# SWM260 register map
File version: 1.0
SWM260 Microcontroller registers
CPU: CM0 r1p0, little endian, 2 interrupt priority bits
Registers are 32-bit, read-write, no defined reset value unless marked. A register's access mark holds for its fields unless they carry their own. Offsets are from the block's base; lines under a group give offsets from that group; [hi:lo] are bit positions; {n}, {i} and the like mark numbered series; 'fields as' and 'values as' point back to an identical list; <NAME> marks a mode.

## Memory map
0x40000000 SYS size 0xAA088 — Registers group
0x40000800 DMA size 0x140 — Registers group
0x40040000 GPIOA size 0x80 — Registers group
0x40040800 GPIOB size 0x80
0x40041000 GPIOC size 0x80
0x40041800 GPIOD size 0x80
0x40042000 UART0 size 0x1C — Registers group
0x40042800 UART1 size 0x1C
0x40043000 UART2 size 0x1C
0x40043800 UART3 size 0x1C
0x40044000 SPI0 size 0x14 — Registers group
0x40044800 SPI1 size 0x14
0x40045000 I2C4 size 0x34 — Registers group
0x40046000 PWM0 size 0x3C — Registers group
0x40046040 PWM1 size 0x3C
0x40046080 PWM2 size 0x3C
0x400460C0 PWM3 size 0x3C
0x40046200 PWMG size 0x48 — Registers group
0x40046800 TIMR0 size 0x30 — Registers group
0x40046840 TIMR1 size 0x30
0x40046880 TIMR2 size 0x30
0x400468C0 TIMR3 size 0x30
0x40046C00 TIMRG size 0x44 — Registers group
0x40048800 BTIMR0 size 0x30
0x40048840 BTIMR1 size 0x30
0x40048880 BTIMR2 size 0x30
0x400488C0 BTIMR3 size 0x30
0x40048C00 BTIMRG size 0x44
0x40049000 ADC0 size 0xFC — Registers group
0x4004A000 FMC size 0x24 — Registers group
0x4004B800 RTC size 0x6C — Registers group
0x400A0000 PORTA size 0x404 — Registers group
0x400A0010 PORTB size 0x404
0x400A0020 PORTC size 0x404
0x400A0030 PORTD size 0x404
0x400A0800 WDT size 0x14 — Registers group
0x400A3000 UART4 size 0x1C

## SYS — Registers group
Base 0x40000000
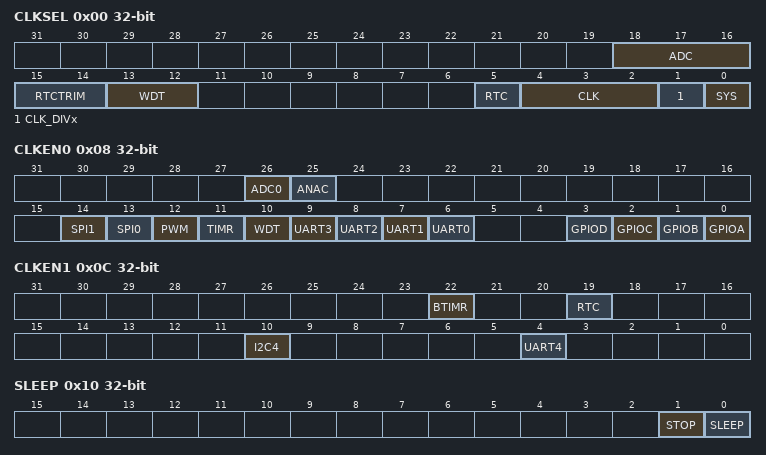
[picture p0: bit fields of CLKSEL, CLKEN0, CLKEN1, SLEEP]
0x00 CLKSEL
  [18:16] ADC, [15:14] RTCTRIM, [13:12] WDT, [5] RTC, [4:2] CLK, [1] CLK_DIVx, [0] SYS
0x04 CLKDIVx_ON
0x08 CLKEN0
  [26] ADC0, [25] ANAC, [14] SPI1, [13] SPI0, [12] PWM, [11] TIMR, [10] WDT, [n+6] UART{n} (n=0..3), [3] GPIOD, [2] GPIOC, [1] GPIOB, [0] GPIOA
0x0C CLKEN1
  [22] BTIMR, [19] RTC, [10] I2C4, [4] UART4
0x10 SLEEP
  [1] STOP, [0] SLEEP
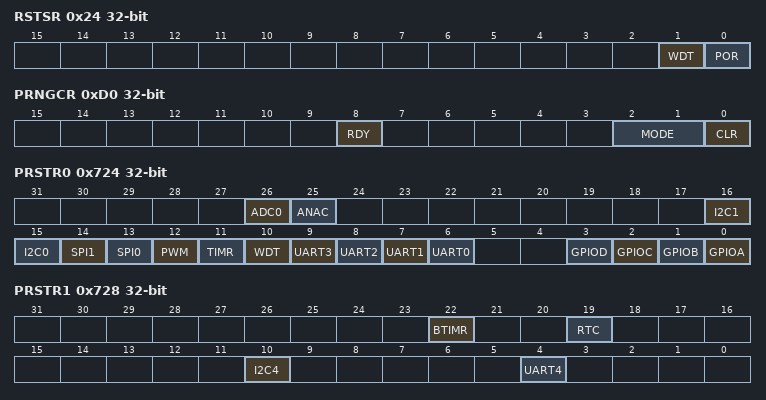
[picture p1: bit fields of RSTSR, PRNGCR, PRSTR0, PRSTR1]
0x24 RSTSR
  [1] WDT, [0] POR
0x30 RTCWKCR
  [0] EN
0x34 RTCWKSR
  [0] FLAG
{0x80+4i} CHIPID[{i}] (i=0..3) ro
{0x90+4i} BACKUP[{i}] (i=0..3)
0xD0 PRNGCR
  [8] RDY, [2:1] MODE, [0] CLR
0xD4 PRNGDL
0xD8 PRNGDH
0x100 PAWKEN
0x104 PBWKEN
0x108 PCWKEN
0x10C PDWKEN
0x130 PAWKSR
0x134 PBWKSR
0x138 PCWKSR
0x13C PDWKSR
0x720 PRSTEN
0x724 PRSTR0
  [26] ADC0, [25] ANAC, [16] I2C1, [15] I2C0, [14] SPI1, [13] SPI0, [12] PWM, [11] TIMR, [10] WDT, [n+6] UART{n} (n=0..3), [3] GPIOD, [2] GPIOC, [1] GPIOB, [0] GPIOA
0x728 PRSTR1
  [22] BTIMR, [19] RTC, [10] I2C4, [4] UART4
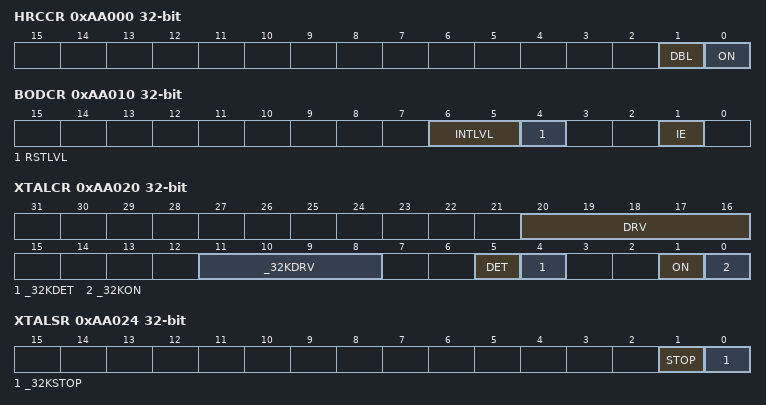
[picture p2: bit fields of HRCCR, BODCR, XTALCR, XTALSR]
0xAA000 HRCCR
  [1] DBL, [0] ON
0xAA010 BODCR
  [6:5] INTLVL, [4] RSTLVL, [1] IE
0xAA014 BODSR
  [0] IF
0xAA020 XTALCR
  [20:16] DRV, [11:8] _32KDRV, [5] DET, [4] _32KDET, [1] ON, [0] _32KON
0xAA024 XTALSR
  [1] STOP, [0] _32KSTOP
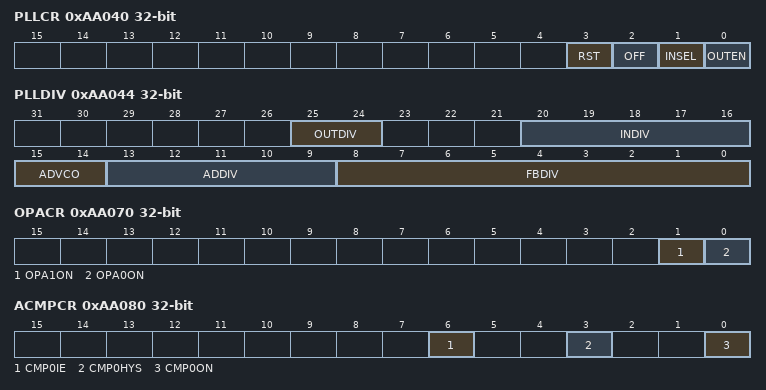
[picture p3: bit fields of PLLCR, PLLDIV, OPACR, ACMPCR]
0xAA040 PLLCR
  [3] RST, [2] OFF, [1] INSEL, [0] OUTEN
0xAA044 PLLDIV
  [25:24] OUTDIV, [20:16] INDIV, [15:14] ADVCO, [13:9] ADDIV, [8:0] FBDIV
0xAA04C PLLLOCK
0xAA050 LRCCR
  [0] ON
0xAA070 OPACR
  [1] OPA1ON, [0] OPA0ON
0xAA080 ACMPCR
  [6] CMP0IE, [3] CMP0HYS, [0] CMP0ON
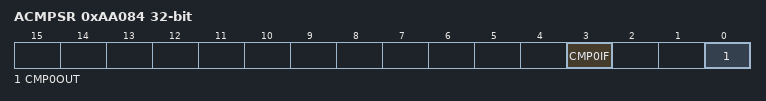
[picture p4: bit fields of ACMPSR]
0xAA084 ACMPSR
  [3] CMP0IF, [0] CMP0OUT

## PORTA — Registers group
Base 0x400A0000
Same registers: PORTB 0x400A0010, PORTC 0x400A0020, PORTD 0x400A0030
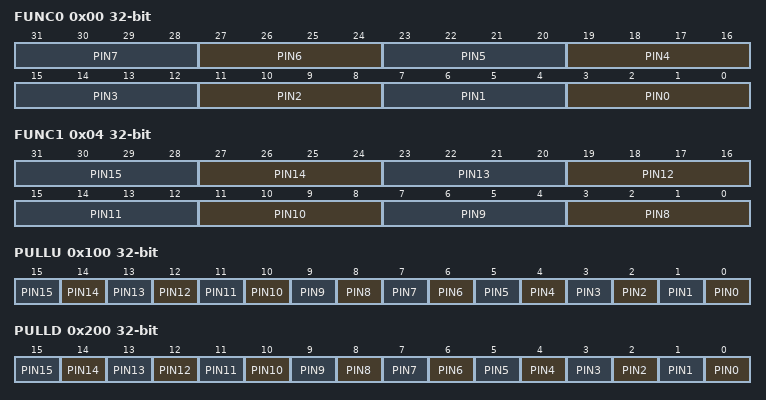
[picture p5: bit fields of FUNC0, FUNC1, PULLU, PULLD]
0x00 FUNC0
  [4n+3:4n] PIN{n} (n=0..7)
0x04 FUNC1
  [4n-29:4n-32] PIN{n} (n=8..15)
0x100 PULLU
  [n] PIN{n} (n=0..15)
0x200 PULLD
  [n] PIN{n} (n=0..15)
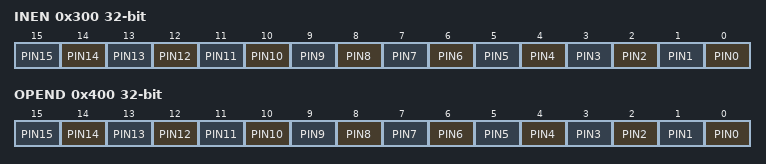
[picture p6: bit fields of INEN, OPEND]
0x300 INEN
  [n] PIN{n} (n=0..15)
0x400 OPEND
  [n] PIN{n} (n=0..15)

## GPIOA — Registers group
Base 0x40040000
Same registers: GPIOB 0x40040800, GPIOC 0x40041000, GPIOD 0x40041800
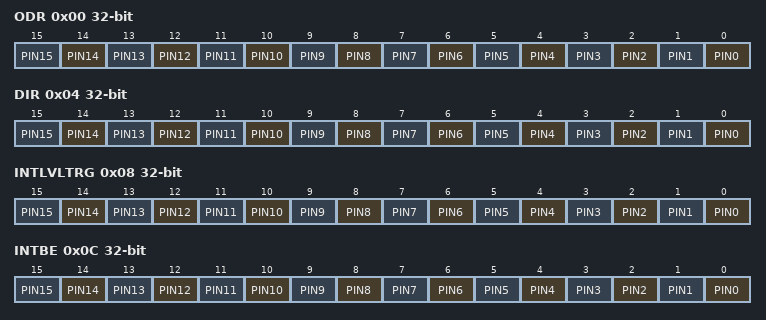
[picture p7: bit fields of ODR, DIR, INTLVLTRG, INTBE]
0x00 ODR
  [n] PIN{n} (n=0..15)
0x04 DIR
  [n] PIN{n} (n=0..15)
0x08 INTLVLTRG
  [n] PIN{n} (n=0..15)
0x0C INTBE
  [n] PIN{n} (n=0..15)
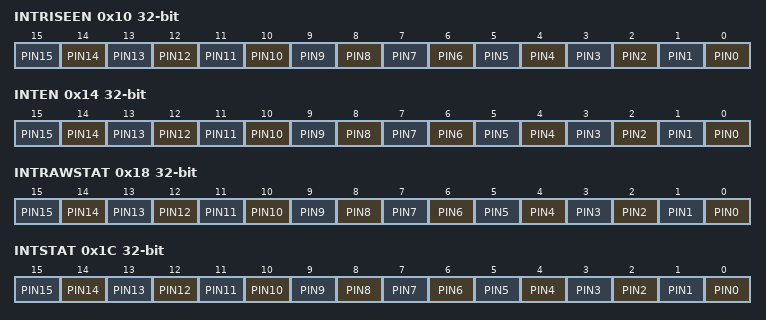
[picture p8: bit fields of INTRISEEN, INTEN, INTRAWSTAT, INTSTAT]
0x10 INTRISEEN
  [n] PIN{n} (n=0..15)
0x14 INTEN
  [n] PIN{n} (n=0..15)
0x18 INTRAWSTAT
  [n] PIN{n} (n=0..15)
0x1C INTSTAT
  [n] PIN{n} (n=0..15)
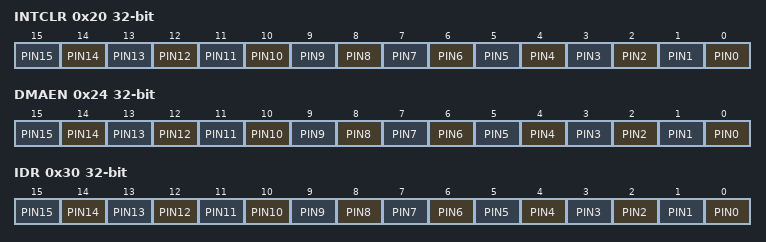
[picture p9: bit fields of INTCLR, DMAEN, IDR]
0x20 INTCLR
  [n] PIN{n} (n=0..15)
0x24 DMAEN
  [n] PIN{n} (n=0..15)
0x30 IDR
  [n] PIN{n} (n=0..15)
{0x40+4i} DATAPIN{i} (i=0..15)
